VERSION ""

NS_ :

BS_:

BU_: MASTER SLAVE
VAL_TABLE_ BMS_fault 3 "0x3: Level 3 fault (critical)" 2 "0x2: Secondary fault (warning)" 0 "0x0: normal" 1 "0x1: Level 1 fault (minor)" ;
VAL_TABLE_ Normal 0 "Description for the value '0x0'" ;

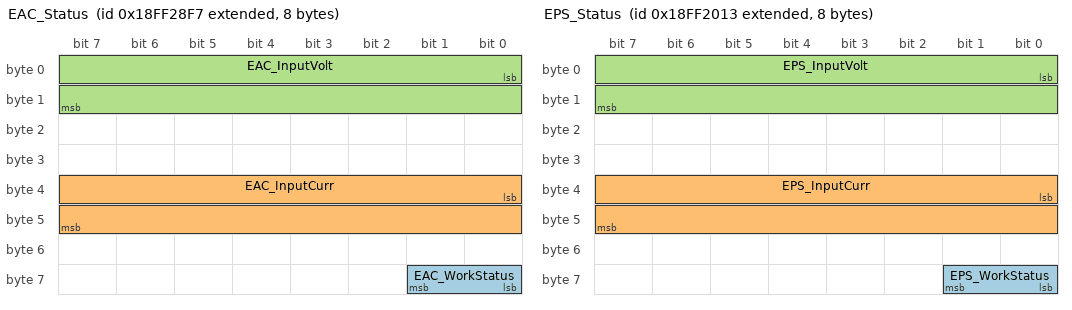
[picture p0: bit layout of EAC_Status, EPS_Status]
BO_ 2566858999 EAC_Status: 8 Vector__XXX
 SG_ EAC_WorkStatus : 56|2@1+ (1,0) [0|3] "" Vector__XXX
 SG_ EAC_InputCurr : 32|16@1+ (0.1,0) [0|100] " A" Vector__XXX
 SG_ EAC_InputVolt : 0|16@1+ (0.1,0) [0|1000] " V" Vector__XXX

BO_ 2566856723 EPS_Status: 8 Vector__XXX
 SG_ EPS_WorkStatus : 56|2@1+ (1,0) [0|3] "" Vector__XXX
 SG_ EPS_InputCurr : 32|16@1+ (0.1,0) [0|100] " A" Vector__XXX
 SG_ EPS_InputVolt : 0|16@1+ (0.1,0) [0|1000] " V" Vector__XXX

BO_ 2566832622 IC_VehicleDistance: 8 Vector__XXX
 SG_ IC_Mileage : 0|32@1+ (0.005,0) [0|21474836.475] " km" Vector__XXX

BO_ 2365484270 IC_Tachograph_VehicleSpeed: 8 Vector__XXX
 SG_ IC_Tachograph_VehicleSpeed : 48|16@1+ (0.00390625,0) [0|255.99609375] " km/h" Vector__XXX

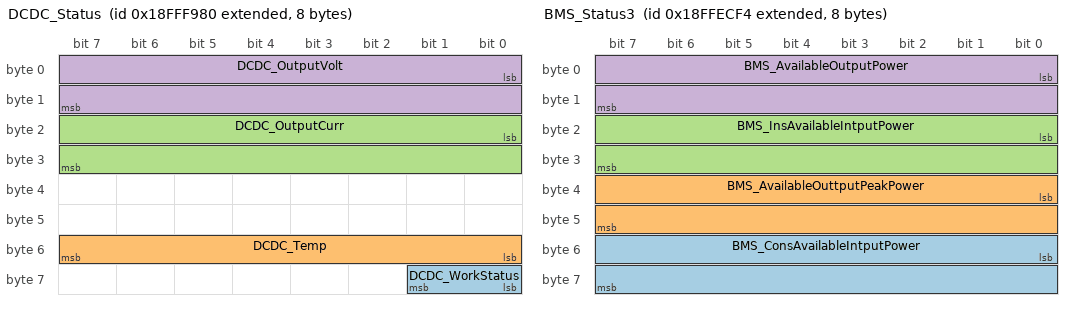
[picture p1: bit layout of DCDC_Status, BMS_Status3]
BO_ 2566912384 DCDC_Status: 8 Vector__XXX
 SG_ DCDC_WorkStatus : 56|2@1+ (1,0) [0|3] "" Vector__XXX
 SG_ DCDC_Temp : 48|8@1+ (1,-40) [-40|215] " ?" Vector__XXX
 SG_ DCDC_OutputCurr : 16|16@1+ (0.05,0) [0|3276.75] " A" Vector__XXX
 SG_ DCDC_OutputVolt : 0|16@1+ (0.05,0) [0|3276.75] " V" Vector__XXX

BO_ 2566908404 BMS_Status6: 1 Vector__XXX
 SG_ BMS_TotalVoltFault : 3|2@1+ (1,0) [0|3] "" Vector__XXX
 SG_ BMS_FaultLevel : 0|3@1+ (1,0) [0|7] ""  MASTER

BO_ 2566910452 BMS_Status5: 8 Vector__XXX
 SG_ BMS_NominalVolt : 48|16@1+ (1,0) [0|65535] " V" Vector__XXX
 SG_ BMS_NominalCapacity : 32|16@1+ (0.1,0) [0|6553.5] " Ah" Vector__XXX

BO_ 2566909172 BMS_Status3: 8 Vector__XXX
 SG_ BMS_ConsAvailableIntputPower : 48|16@1+ (10,0) [0|655350] " W" Vector__XXX
 SG_ BMS_AvailableOuttputPeakPower : 32|16@1+ (10,0) [0|655350] " W" Vector__XXX
 SG_ BMS_InsAvailableIntputPower : 16|16@1+ (10,0) [0|655350] " W" Vector__XXX
 SG_ BMS_AvailableOutputPower : 0|16@1+ (10,0) [0|655350] " W" Vector__XXX

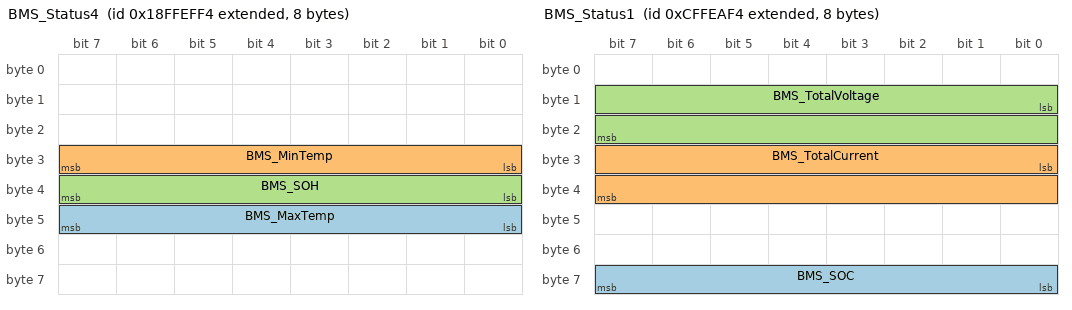
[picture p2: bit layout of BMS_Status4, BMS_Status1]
BO_ 2566909940 BMS_Status4: 8 Vector__XXX
 SG_ BMS_MaxTemp : 40|8@1+ (1,-40) [-40|215] " ?" Vector__XXX
 SG_ BMS_MinTemp : 24|8@1+ (1,-40) [-40|215] " ?" Vector__XXX
 SG_ BMS_SOH : 32|8@1+ (1,0) [0|100] " %" Vector__XXX

BO_ 2566908916 BMS_Status2: 8 Vector__XXX
 SG_ BMS_MaxCellVolt : 32|16@1+ (0.001,0) [0|65.535] " V" Vector__XXX
 SG_ BMS_MinCellVolt : 0|16@1+ (0.001,0) [0|65.535] " V" Vector__XXX

BO_ 2365582068 BMS_Status1: 8 Vector__XXX
 SG_ BMS_SOC : 56|8@1+ (1,0) [0|100] " %" Vector__XXX
 SG_ BMS_TotalCurrent : 24|16@1+ (0.1,-600) [-600|5953.5] " A" Vector__XXX
 SG_ BMS_TotalVoltage : 8|16@1+ (0.1,0) [0|6553.5] " V" Vector__XXX

BO_ 2566849263 MCU_Status2: 8 Vector__XXX
 SG_ MCU_MotorControllerTemp : 56|8@1+ (1,-40) [-40|215] " ?" Vector__XXX
 SG_ MCU_MotorTemp : 48|8@1+ (1,-40) [-40|215] " ?" Vector__XXX

BO_ 2365522415 MCU_Status1: 8 Vector__XXX
 SG_ MCU_OutputTorque : 48|16@1+ (1,-10000) [-10000|55535] " NM" Vector__XXX
 SG_ MCU_OutputSpeed : 32|16@1+ (1,-10000) [-10000|55535] " RPM" Vector__XXX

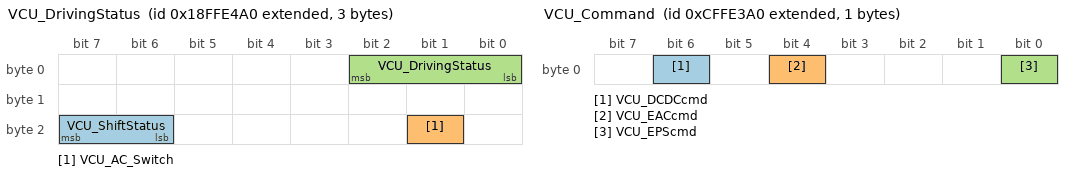
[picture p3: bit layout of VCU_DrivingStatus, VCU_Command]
BO_ 2566907040 VCU_DrivingStatus: 3 Vector__XXX
 SG_ VCU_ShiftStatus : 22|2@1+ (1,0) [0|3] "" Vector__XXX
 SG_ VCU_AC_Switch : 17|1@1+ (1,0) [0|1] "" Vector__XXX
 SG_ VCU_DrivingStatus : 0|3@1+ (1,0) [0|7] "" Vector__XXX

BO_ 2365579680 VCU_BrakePedalValue: 8 Vector__XXX
 SG_ VCU_BrakePedal : 9|1@1+ (1,0) [0|1] "" Vector__XXX

BO_ 2565866400 VCU_AcceleratorPedalValue: 8 Vector__XXX
 SG_ VCU_AcceleratorPedalValue : 8|8@1+ (0.4,0) [0|102] " %" Vector__XXX

BO_ 2365580192 VCU_Command: 1 Vector__XXX
 SG_ VCU_DCDCcmd : 6|1@1+ (1,0) [0|1] "" Vector__XXX
 SG_ VCU_EACcmd : 4|1@1+ (1,0) [0|1] "" Vector__XXX
 SG_ VCU_EPScmd : 0|1@1+ (1,0) [0|1] "" Vector__XXX

CM_ SG_ 2566858999 EAC_WorkStatus "Air pump status
0x0: stop
0x1: Ready
0x2: Run
0x3: failure";
CM_ SG_ 2566858999 EAC_InputCurr "Air pump real-time current";
CM_ SG_ 2566858999 EAC_InputVolt "Air pump real-time voltage";
CM_ SG_ 2566856723 EPS_WorkStatus "Steering pump status
0x0: stop
0x1: Ready
0x2: Run
0x3: failure";
CM_ SG_ 2566856723 EPS_InputCurr "Steering pump real-time current";
CM_ SG_ 2566856723 EPS_InputVolt "Steering pump real-time voltage";
CM_ SG_ 2566832622 IC_Mileage "Total mileage";
CM_ SG_ 2365484270 IC_Tachograph_VehicleSpeed "Speed";
CM_ SG_ 2566912384 DCDC_WorkStatus "DCD COperating status
0x0: stop
0x1: Ready
0x2: Run
0x3: failure";
CM_ SG_ 2566912384 DCDC_Temp "DCDC Module temperature";
CM_ SG_ 2566912384 DCDC_OutputCurr "DCDC Output current";
CM_ SG_ 2566912384 DCDC_OutputVolt "DCDC output voltage";
CM_ SG_ 2566908404 BMS_TotalVoltFault "Battery pack voltage is abnormal
0x0: normal
0x1: The total voltage of the battery pack is too high
0x2: The total voltage of the battery pack is too low";
CM_ SG_ 2566908404 BMS_FaultLevel "Battery failure level,
0x0: normal
0x1: Level 1 fault (minor)
0x2: Secondary fault (warning)
0x3: Level 3 fault (critical)";
CM_ SG_ 2566910452 BMS_NominalVolt "Nominal voltage of battery pack";
CM_ SG_ 2566910452 BMS_NominalCapacity "Nominal capacity of battery pack";
CM_ SG_ 2566909172 BMS_ConsAvailableIntputPower "Continuous available feedback power";
CM_ SG_ 2566909172 BMS_AvailableOuttputPeakPower "Maximum available discharge peak power (30s)";
CM_ SG_ 2566909172 BMS_InsAvailableIntputPower "Available energy feedback power (instantaneous 10s)";
CM_ SG_ 2566909172 BMS_AvailableOutputPower "Available driving output power (continuous)";
CM_ SG_ 2566909940 BMS_MaxTemp "The highest battery temperature point temperature";
CM_ SG_ 2566909940 BMS_MinTemp "Battery minimum temperature point temperature";
CM_ SG_ 2566909940 BMS_SOH "SOH";
CM_ SG_ 2566908916 BMS_MaxCellVolt "Max Cell Voltage";
CM_ SG_ 2566908916 BMS_MinCellVolt "Min Cell Voltage";
CM_ SG_ 2365582068 BMS_SOC "Battery SOC real";
CM_ SG_ 2365582068 BMS_TotalCurrent "Battery Current";
CM_ SG_ 2365582068 BMS_TotalVoltage "Battery Total Voltage";
CM_ SG_ 2566849263 MCU_MotorControllerTemp "Motor controller temperature";
CM_ SG_ 2566849263 MCU_MotorTemp "Motor temperature";
CM_ SG_ 2365522415 MCU_OutputTorque "Motor torque";
CM_ SG_ 2365522415 MCU_OutputSpeed "MCU_OutputSpeed";
CM_ SG_ 2566907040 VCU_ShiftStatus "0x0: N file
0x1: D file
0x2: R file";
CM_ SG_ 2566907040 VCU_AC_Switch "0x0: disconnect
0x1: closed";
CM_ SG_ 2566907040 VCU_DrivingStatus "0x0: reserved
0x1: Low voltage power on
0x2: High voltage power on
0x3: Driving state
0x4-0x6: reserved
0x7: fault";
CM_ SG_ 2365579680 VCU_BrakePedal "0x0: no foot brake
0x1: The foot brake is effective";
CM_ SG_ 2565866400 VCU_AcceleratorPedalValue "Accelerator pedal status";
CM_ SG_ 2365580192 VCU_DCDCcmd "DCDC enable indication,0x0: not enabled,0x1: enable";
CM_ SG_ 2365580192 VCU_EACcmd "Brake DCAC enable command,0x0: not enabled,0x1: enable";
CM_ SG_ 2365580192 VCU_EPScmd "Turn to DCAC enable command,0x0: not enabled,0x1: enable";
BA_DEF_ SG_  "GenSigStartValue" HEX 0 0;
BA_DEF_ SG_  "GenSigSendType" ENUM  "Cycle","OnChange";
BA_DEF_DEF_  "GenSigStartValue" 0;
BA_DEF_DEF_  "GenSigSendType" "Cycle";
BA_ "GenSigStartValue" SG_ 2566912384 DCDC_Temp 40;
BA_ "GenSigStartValue" SG_ 2566909940 BMS_MaxTemp 40;
BA_ "GenSigStartValue" SG_ 2566909940 BMS_MinTemp 40;
BA_ "GenSigStartValue" SG_ 2365582068 BMS_TotalCurrent 6000;
BA_ "GenSigStartValue" SG_ 2566849263 MCU_MotorControllerTemp 40;
BA_ "GenSigStartValue" SG_ 2566849263 MCU_MotorTemp 40;
BA_ "GenSigStartValue" SG_ 2365522415 MCU_OutputTorque 10000;
BA_ "GenSigStartValue" SG_ 2365522415 MCU_OutputSpeed 10000;
